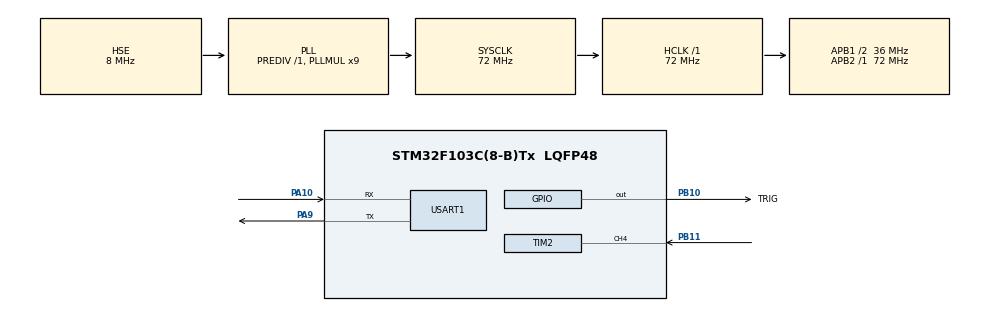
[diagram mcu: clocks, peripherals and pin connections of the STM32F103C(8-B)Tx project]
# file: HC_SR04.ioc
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Mcu.Family=STM32F1
Mcu.Name=STM32F103C(8-B)Tx
Mcu.Package=LQFP48
NVIC.PriorityGroup=NVIC_PRIORITYGROUP_4
NVIC.TIM2_IRQn=true\:0\:0\:false\:false\:true\:true\:true\:true
NVIC.USART1_IRQn=true\:0\:0\:false\:false\:true\:true\:true\:true
PA10.Mode=Asynchronous
PA10.Signal=USART1_RX
PA13.Mode=Serial_Wire
PA13.Signal=SYS_JTMS-SWDIO
PA14.Mode=Serial_Wire
PA14.Signal=SYS_JTCK-SWCLK
PA9.Mode=Asynchronous
PA9.Signal=USART1_TX
PB10.GPIO_Label=TRIG
PB10.GPIO_PuPd=GPIO_PULLDOWN
PB10.Signal=GPIO_Output
PB11.Signal=S_TIM2_CH4
PC14-OSC32_IN.Mode=LSE-External-Oscillator
PC14-OSC32_IN.Signal=RCC_OSC32_IN
PC15-OSC32_OUT.Mode=LSE-External-Oscillator
PC15-OSC32_OUT.Signal=RCC_OSC32_OUT
PD0-OSC_IN.Mode=HSE-External-Oscillator
PD0-OSC_IN.Signal=RCC_OSC_IN
PD1-OSC_OUT.Mode=HSE-External-Oscillator
PD1-OSC_OUT.Signal=RCC_OSC_OUT
ProjectManager.HeapSize=0x200
ProjectManager.StackSize=0x400
ProjectManager.TargetToolchain=MDK-ARM V5.32
RCC.AHBFreq_Value=72000000
RCC.APB1CLKDivider=RCC_HCLK_DIV2
RCC.APB1Freq_Value=36000000
RCC.APB1TimFreq_Value=72000000
RCC.APB2Freq_Value=72000000
RCC.APB2TimFreq_Value=72000000
RCC.HCLKFreq_Value=72000000
RCC.PLLMUL=RCC_PLL_MUL9
RCC.PLLSourceVirtual=RCC_PLLSOURCE_HSE
RCC.SYSCLKFreq_VALUE=72000000
RCC.SYSCLKSource=RCC_SYSCLKSOURCE_PLLCLK
RCC.USBFreq_Value=72000000
SH.S_TIM2_CH4.0=TIM2_CH4,Input_Capture4_from_TI4
TIM2.Channel-Input_Capture4_from_TI4=TIM_CHANNEL_4
TIM2.Prescaler=72-1
USART1.VirtualMode=VM_ASYNC
board=custom

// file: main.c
/* USER CODE BEGIN Header */
/**
  ******************************************************************************
  * @file           : main.c
  * @brief          : Main program body
  ******************************************************************************
  * @attention
  *
  * Copyright (c) 2025 STMicroelectronics.
  * All rights reserved.
  *
  * This software is licensed under terms that can be found in the LICENSE file
  * in the root directory of this software component.
  * If no LICENSE file comes with this software, it is provided AS-IS.
  *
  ******************************************************************************
  */
/* USER CODE END Header */
#include "main.h"

/* USER CODE BEGIN Includes */
#include "sr04.h"
#include <stdio.h>

/* USER CODE END Includes */

TIM_HandleTypeDef htim2;

UART_HandleTypeDef huart1;

void SystemClock_Config(void);
static void MX_GPIO_Init(void);
static void MX_TIM2_Init(void);
static void MX_USART1_UART_Init(void);

/* USER CODE BEGIN 0 */

int fputc(int ch, FILE *f)
{
  HAL_UART_Transmit(&huart1, (uint8_t*)&ch, 1, HAL_MAX_DELAY);
  return ch;
}

/**
 * @description: 定时器输出捕获中断
 * @param {TIM_HandleTypeDef} *htim
 * @return {*}
 */
void HAL_TIM_IC_CaptureCallback(TIM_HandleTypeDef *htim)
{
  Hcsr04TimIcIsr(htim);
}

/**
 * @description: 定时器溢出中断
 * @param {*}
 * @return {*}
 */
void HAL_TIM_PeriodElapsedCallback(TIM_HandleTypeDef* htim)
{
  Hcsr04TimOverflowIsr(htim);
}

/* USER CODE END 0 */

int main(void)
{

  /* MCU Configuration--------------------------------------------------------*/

  /* Reset of all peripherals, Initializes the Flash interface and the Systick. */
  HAL_Init();

  /* Configure the system clock */
  SystemClock_Config();

  /* Initialize all configured peripherals */
  MX_GPIO_Init();
  MX_TIM2_Init();
  MX_USART1_UART_Init();
  /* USER CODE BEGIN 2 */
  Hcsr04Init(&htim2, TIM_CHANNEL_4);
  Hcsr04Start();
  /* USER CODE END 2 */

  /* Infinite loop */
  /* USER CODE BEGIN WHILE */
  while (1)
  {
    printf("distance:%.1f cm\r\n", Hcsr04Read());
    Hcsr04Start();
    HAL_Delay(200); //  测距周期200ms
    /* USER CODE END WHILE */

  }
}

void SystemClock_Config(void)
{
  RCC_OscInitTypeDef RCC_OscInitStruct = {0};
  RCC_ClkInitTypeDef RCC_ClkInitStruct = {0};

  /** Initializes the RCC Oscillators according to the specified parameters
  * in the RCC_OscInitTypeDef structure.
  */
  RCC_OscInitStruct.OscillatorType = RCC_OSCILLATORTYPE_HSE;
  RCC_OscInitStruct.HSEState = RCC_HSE_ON;
  RCC_OscInitStruct.HSEPredivValue = RCC_HSE_PREDIV_DIV1;
  RCC_OscInitStruct.HSIState = RCC_HSI_ON;
  RCC_OscInitStruct.PLL.PLLState = RCC_PLL_ON;
  RCC_OscInitStruct.PLL.PLLSource = RCC_PLLSOURCE_HSE;
  RCC_OscInitStruct.PLL.PLLMUL = RCC_PLL_MUL9;
  if (HAL_RCC_OscConfig(&RCC_OscInitStruct) != HAL_OK)
  {
    Error_Handler();
  }

  /** Initializes the CPU, AHB and APB buses clocks
  */
  RCC_ClkInitStruct.ClockType = RCC_CLOCKTYPE_HCLK|RCC_CLOCKTYPE_SYSCLK
                              |RCC_CLOCKTYPE_PCLK1|RCC_CLOCKTYPE_PCLK2;
  RCC_ClkInitStruct.SYSCLKSource = RCC_SYSCLKSOURCE_PLLCLK;
  RCC_ClkInitStruct.AHBCLKDivider = RCC_SYSCLK_DIV1;
  RCC_ClkInitStruct.APB1CLKDivider = RCC_HCLK_DIV2;
  RCC_ClkInitStruct.APB2CLKDivider = RCC_HCLK_DIV1;

  if (HAL_RCC_ClockConfig(&RCC_ClkInitStruct, FLASH_LATENCY_2) != HAL_OK)
  {
    Error_Handler();
  }
}

static void MX_TIM2_Init(void)
{

  TIM_MasterConfigTypeDef sMasterConfig = {0};
  TIM_IC_InitTypeDef sConfigIC = {0};

  htim2.Instance = TIM2;
  htim2.Init.Prescaler = 72-1;
  htim2.Init.CounterMode = TIM_COUNTERMODE_UP;
  htim2.Init.Period = 65535;
  htim2.Init.ClockDivision = TIM_CLOCKDIVISION_DIV1;
  htim2.Init.AutoReloadPreload = TIM_AUTORELOAD_PRELOAD_DISABLE;
  if (HAL_TIM_IC_Init(&htim2) != HAL_OK)
  {
    Error_Handler();
  }
  sMasterConfig.MasterOutputTrigger = TIM_TRGO_RESET;
  sMasterConfig.MasterSlaveMode = TIM_MASTERSLAVEMODE_DISABLE;
  if (HAL_TIMEx_MasterConfigSynchronization(&htim2, &sMasterConfig) != HAL_OK)
  {
    Error_Handler();
  }
  sConfigIC.ICPolarity = TIM_INPUTCHANNELPOLARITY_RISING;
  sConfigIC.ICSelection = TIM_ICSELECTION_DIRECTTI;
  sConfigIC.ICPrescaler = TIM_ICPSC_DIV1;
  sConfigIC.ICFilter = 0;
  if (HAL_TIM_IC_ConfigChannel(&htim2, &sConfigIC, TIM_CHANNEL_4) != HAL_OK)
  {
    Error_Handler();
  }

}

static void MX_USART1_UART_Init(void)
{

  huart1.Instance = USART1;
  huart1.Init.BaudRate = 115200;
  huart1.Init.WordLength = UART_WORDLENGTH_8B;
  huart1.Init.StopBits = UART_STOPBITS_1;
  huart1.Init.Parity = UART_PARITY_NONE;
  huart1.Init.Mode = UART_MODE_TX_RX;
  huart1.Init.HwFlowCtl = UART_HWCONTROL_NONE;
  huart1.Init.OverSampling = UART_OVERSAMPLING_16;
  if (HAL_UART_Init(&huart1) != HAL_OK)
  {
    Error_Handler();
  }

}

static void MX_GPIO_Init(void)
{
  GPIO_InitTypeDef GPIO_InitStruct = {0};

  /* GPIO Ports Clock Enable */
  __HAL_RCC_GPIOC_CLK_ENABLE();
  __HAL_RCC_GPIOD_CLK_ENABLE();
  __HAL_RCC_GPIOB_CLK_ENABLE();
  __HAL_RCC_GPIOA_CLK_ENABLE();

  /*Configure GPIO pin Output Level */
  HAL_GPIO_WritePin(TRIG_GPIO_Port, TRIG_Pin, GPIO_PIN_RESET);

  /*Configure GPIO pin : TRIG_Pin */
  GPIO_InitStruct.Pin = TRIG_Pin;
  GPIO_InitStruct.Mode = GPIO_MODE_OUTPUT_PP;
  GPIO_InitStruct.Pull = GPIO_PULLDOWN;
  GPIO_InitStruct.Speed = GPIO_SPEED_FREQ_LOW;
  HAL_GPIO_Init(TRIG_GPIO_Port, &GPIO_InitStruct);

}

void Error_Handler(void)
{
  __disable_irq();
  while (1)
  {
  }
}
